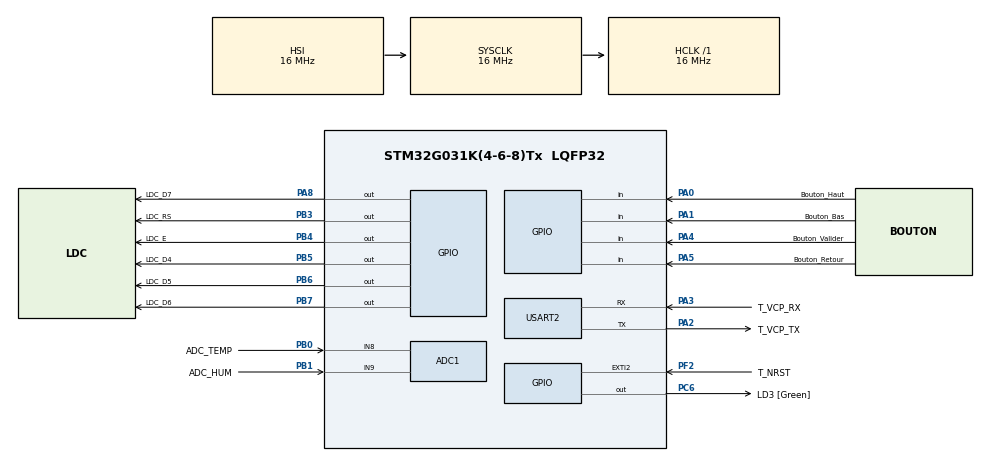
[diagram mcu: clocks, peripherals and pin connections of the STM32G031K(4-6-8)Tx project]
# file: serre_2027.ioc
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ADC1.Channel-0\#ChannelRegularConversion=ADC_CHANNEL_8
ADC1.NbrOfConversionFlag=1
ADC1.Rank-0\#ChannelRegularConversion=1
ADC1.SamplingTime-0\#ChannelRegularConversion=ADC_SAMPLINGTIME_COMMON_1
ADC1.SelectedChannel=ADC_CHANNEL_8|ADC_CHANNEL_9
ADC1.master=1
Mcu.Family=STM32G0
Mcu.Name=STM32G031K(4-6-8)Tx
Mcu.Package=LQFP32
PA0.GPIO_Label=Bouton_Haut
PA0.GPIO_PuPd=GPIO_PULLUP
PA0.Signal=GPIO_Input
PA1.GPIO_Label=Bouton_Bas
PA1.GPIO_PuPd=GPIO_PULLUP
PA1.Signal=GPIO_Input
PA13.GPIO_Label=T_JTMS
PA13.Mode=Serial_Wire
PA13.Signal=SYS_SWDIO
PA14-BOOT0.GPIO_Label=T_JTCK
PA14-BOOT0.Mode=Serial_Wire
PA14-BOOT0.Signal=SYS_SWCLK
PA2.GPIO_Label=T_VCP_TX
PA2.GPIO_PuPd=GPIO_PULLUP
PA2.Mode=Asynchronous
PA2.Signal=USART2_TX
PA3.GPIO_Label=T_VCP_RX
PA3.GPIO_PuPd=GPIO_PULLUP
PA3.Mode=Asynchronous
PA3.Signal=USART2_RX
PA4.GPIO_Label=Bouton_Valider
PA4.GPIO_PuPd=GPIO_PULLUP
PA4.Signal=GPIO_Input
PA5.GPIO_Label=Bouton_Retour
PA5.GPIO_PuPd=GPIO_PULLUP
PA5.Signal=GPIO_Input
PA8.GPIO_Label=LDC_D7
PA8.Signal=GPIO_Output
PB0.GPIO_Label=ADC_TEMP
PB0.Mode=IN8
PB0.Signal=ADC1_IN8
PB1.GPIO_Label=ADC_HUM
PB1.Mode=IN9
PB1.Signal=ADC1_IN9
PB3.GPIO_Label=LDC_RS
PB3.Signal=GPIO_Output
PB4.GPIO_Label=LDC_E
PB4.Signal=GPIO_Output
PB5.GPIO_Label=LDC_D4
PB5.Signal=GPIO_Output
PB6.GPIO_Label=LDC_D5
PB6.Signal=GPIO_Output
PB7.GPIO_Label=LDC_D6
PB7.Signal=GPIO_Output
PB8.GPIO_Label=PWM_Pompe
PB8.Signal=S_TIM16_CH1
PB9.GPIO_Label=PWM_Ventilo
PB9.Signal=S_TIM17_CH1
PC14-OSC32_IN\ (PC14).Mode=LSE-External-Oscillator
PC14-OSC32_IN\ (PC14).Signal=RCC_OSC32_IN
PC15-OSC32_OUT\ (PC15).Mode=LSE-External-Oscillator
PC15-OSC32_OUT\ (PC15).Signal=RCC_OSC32_OUT
PC6.GPIO_Label=LD3 [Green]
PC6.Signal=GPIO_Output
PF2\ -\ NRST.GPIO_Label=T_NRST
PF2\ -\ NRST.Signal=GPXTI2
ProjectManager.HeapSize=0x200
ProjectManager.StackSize=0x400
ProjectManager.TargetToolchain=STM32CubeIDE
RCC.AHBFreq_Value=16000000
RCC.CortexFreq_Value=16000000
RCC.EXTERNAL_CLOCK_VALUE=12288000
RCC.HCLKFreq_Value=16000000
RCC.HSE_VALUE=8000000
RCC.HSI_VALUE=16000000
RCC.SYSCLKFreq_VALUE=16000000
RCC.VCOOutputFreq_Value=128000000
SH.S_TIM16_CH1.0=TIM16_CH1
SH.S_TIM17_CH1.0=TIM17_CH1
USART2.VirtualMode-Asynchronous=VM_ASYNC
USART2.WordLength=WORDLENGTH_7B
board=NUCLEO-G031K8

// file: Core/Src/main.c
/* USER CODE BEGIN Header */
/**
  ******************************************************************************
  * @file           : main.c
  * @brief          : Main program body
  ******************************************************************************
  * @attention
  *
  * Copyright (c) 2026 STMicroelectronics.
  * All rights reserved.
  *
  * This software is licensed under terms that can be found in the LICENSE file
  * in the root directory of this software component.
  * If no LICENSE file comes with this software, it is provided AS-IS.
  *
  ******************************************************************************
  */
/* USER CODE END Header */
#include "main.h"

ADC_HandleTypeDef hadc1;

UART_HandleTypeDef huart2;

void SystemClock_Config(void);
static void MX_GPIO_Init(void);
static void MX_USART2_UART_Init(void);
static void MX_ADC1_Init(void);

int main(void)
{

  /* MCU Configuration--------------------------------------------------------*/

  /* Reset of all peripherals, Initializes the Flash interface and the Systick. */
  HAL_Init();

  /* Configure the system clock */
  SystemClock_Config();

  /* Initialize all configured peripherals */
  MX_GPIO_Init();
  MX_USART2_UART_Init();
  MX_ADC1_Init();

  /* Infinite loop */
  while (1)
  {

    /* USER CODE BEGIN 3 */
    HAL_GPIO_TogglePin(LD3_GPIO_Port, LD3_Pin);
    HAL_Delay(4000);
    // commentaire
    // test loris
  }
  /* USER CODE END 3 */
}

void SystemClock_Config(void)
{
  RCC_OscInitTypeDef RCC_OscInitStruct = {0};
  RCC_ClkInitTypeDef RCC_ClkInitStruct = {0};

  /** Configure the main internal regulator output voltage
  */
  HAL_PWREx_ControlVoltageScaling(PWR_REGULATOR_VOLTAGE_SCALE1);

  /** Initializes the RCC Oscillators according to the specified parameters
  * in the RCC_OscInitTypeDef structure.
  */
  RCC_OscInitStruct.OscillatorType = RCC_OSCILLATORTYPE_HSI;
  RCC_OscInitStruct.HSIState = RCC_HSI_ON;
  RCC_OscInitStruct.HSIDiv = RCC_HSI_DIV1;
  RCC_OscInitStruct.HSICalibrationValue = RCC_HSICALIBRATION_DEFAULT;
  RCC_OscInitStruct.PLL.PLLState = RCC_PLL_NONE;
  if (HAL_RCC_OscConfig(&RCC_OscInitStruct) != HAL_OK)
  {
    Error_Handler();
  }

  /** Initializes the CPU, AHB and APB buses clocks
  */
  RCC_ClkInitStruct.ClockType = RCC_CLOCKTYPE_HCLK|RCC_CLOCKTYPE_SYSCLK
                              |RCC_CLOCKTYPE_PCLK1;
  RCC_ClkInitStruct.SYSCLKSource = RCC_SYSCLKSOURCE_HSI;
  RCC_ClkInitStruct.AHBCLKDivider = RCC_SYSCLK_DIV1;
  RCC_ClkInitStruct.APB1CLKDivider = RCC_HCLK_DIV1;

  if (HAL_RCC_ClockConfig(&RCC_ClkInitStruct, FLASH_LATENCY_0) != HAL_OK)
  {
    Error_Handler();
  }
}

static void MX_ADC1_Init(void)
{

  ADC_ChannelConfTypeDef sConfig = {0};

  /** Configure the global features of the ADC (Clock, Resolution, Data Alignment and number of conversion)
  */
  hadc1.Instance = ADC1;
  hadc1.Init.ClockPrescaler = ADC_CLOCK_SYNC_PCLK_DIV2;
  hadc1.Init.Resolution = ADC_RESOLUTION_12B;
  hadc1.Init.DataAlign = ADC_DATAALIGN_RIGHT;
  hadc1.Init.ScanConvMode = ADC_SCAN_DISABLE;
  hadc1.Init.EOCSelection = ADC_EOC_SINGLE_CONV;
  hadc1.Init.LowPowerAutoWait = DISABLE;
  hadc1.Init.LowPowerAutoPowerOff = DISABLE;
  hadc1.Init.ContinuousConvMode = DISABLE;
  hadc1.Init.NbrOfConversion = 1;
  hadc1.Init.DiscontinuousConvMode = DISABLE;
  hadc1.Init.ExternalTrigConv = ADC_SOFTWARE_START;
  hadc1.Init.ExternalTrigConvEdge = ADC_EXTERNALTRIGCONVEDGE_NONE;
  hadc1.Init.DMAContinuousRequests = DISABLE;
  hadc1.Init.Overrun = ADC_OVR_DATA_PRESERVED;
  hadc1.Init.SamplingTimeCommon1 = ADC_SAMPLETIME_1CYCLE_5;
  hadc1.Init.SamplingTimeCommon2 = ADC_SAMPLETIME_1CYCLE_5;
  hadc1.Init.OversamplingMode = DISABLE;
  hadc1.Init.TriggerFrequencyMode = ADC_TRIGGER_FREQ_HIGH;
  if (HAL_ADC_Init(&hadc1) != HAL_OK)
  {
    Error_Handler();
  }

  /** Configure Regular Channel
  */
  sConfig.Channel = ADC_CHANNEL_8;
  sConfig.Rank = ADC_REGULAR_RANK_1;
  sConfig.SamplingTime = ADC_SAMPLINGTIME_COMMON_1;
  if (HAL_ADC_ConfigChannel(&hadc1, &sConfig) != HAL_OK)
  {
    Error_Handler();
  }

}

static void MX_USART2_UART_Init(void)
{

  huart2.Instance = USART2;
  huart2.Init.BaudRate = 115200;
  huart2.Init.WordLength = UART_WORDLENGTH_7B;
  huart2.Init.StopBits = UART_STOPBITS_1;
  huart2.Init.Parity = UART_PARITY_NONE;
  huart2.Init.Mode = UART_MODE_TX_RX;
  huart2.Init.HwFlowCtl = UART_HWCONTROL_NONE;
  huart2.Init.OverSampling = UART_OVERSAMPLING_16;
  huart2.Init.OneBitSampling = UART_ONE_BIT_SAMPLE_DISABLE;
  huart2.Init.ClockPrescaler = UART_PRESCALER_DIV1;
  huart2.AdvancedInit.AdvFeatureInit = UART_ADVFEATURE_NO_INIT;
  if (HAL_UART_Init(&huart2) != HAL_OK)
  {
    Error_Handler();
  }

}

static void MX_GPIO_Init(void)
{
  GPIO_InitTypeDef GPIO_InitStruct = {0};

  /* GPIO Ports Clock Enable */
  __HAL_RCC_GPIOB_CLK_ENABLE();
  __HAL_RCC_GPIOC_CLK_ENABLE();
  __HAL_RCC_GPIOF_CLK_ENABLE();
  __HAL_RCC_GPIOA_CLK_ENABLE();

  /*Configure GPIO pin Output Level */
  HAL_GPIO_WritePin(LDC_D7_GPIO_Port, LDC_D7_Pin, GPIO_PIN_RESET);

  /*Configure GPIO pin Output Level */
  HAL_GPIO_WritePin(LD3_GPIO_Port, LD3_Pin, GPIO_PIN_RESET);

  /*Configure GPIO pin Output Level */
  HAL_GPIO_WritePin(GPIOB, LDC_RS_Pin|LDC_E_Pin|LDC_D4_Pin|LDC_D5_Pin
                          |LDC_D6_Pin, GPIO_PIN_RESET);

  /*Configure GPIO pin : PWM_Ventilo_Pin */
  GPIO_InitStruct.Pin = PWM_Ventilo_Pin;
  GPIO_InitStruct.Mode = GPIO_MODE_AF_PP;
  GPIO_InitStruct.Pull = GPIO_NOPULL;
  GPIO_InitStruct.Speed = GPIO_SPEED_FREQ_LOW;
  GPIO_InitStruct.Alternate = GPIO_AF2_TIM17;
  HAL_GPIO_Init(PWM_Ventilo_GPIO_Port, &GPIO_InitStruct);

  /*Configure GPIO pin : T_NRST_Pin */
  GPIO_InitStruct.Pin = T_NRST_Pin;
  GPIO_InitStruct.Mode = GPIO_MODE_IT_RISING;
  GPIO_InitStruct.Pull = GPIO_NOPULL;
  HAL_GPIO_Init(T_NRST_GPIO_Port, &GPIO_InitStruct);

  /*Configure GPIO pins : Bouton_Haut_Pin Bouton_Bas_Pin Bouton_Valider_Pin Bouton_Retour_Pin */
  GPIO_InitStruct.Pin = Bouton_Haut_Pin|Bouton_Bas_Pin|Bouton_Valider_Pin|Bouton_Retour_Pin;
  GPIO_InitStruct.Mode = GPIO_MODE_INPUT;
  GPIO_InitStruct.Pull = GPIO_PULLUP;
  HAL_GPIO_Init(GPIOA, &GPIO_InitStruct);

  /*Configure GPIO pin : LDC_D7_Pin */
  GPIO_InitStruct.Pin = LDC_D7_Pin;
  GPIO_InitStruct.Mode = GPIO_MODE_OUTPUT_PP;
  GPIO_InitStruct.Pull = GPIO_NOPULL;
  GPIO_InitStruct.Speed = GPIO_SPEED_FREQ_LOW;
  HAL_GPIO_Init(LDC_D7_GPIO_Port, &GPIO_InitStruct);

  /*Configure GPIO pin : LD3_Pin */
  GPIO_InitStruct.Pin = LD3_Pin;
  GPIO_InitStruct.Mode = GPIO_MODE_OUTPUT_PP;
  GPIO_InitStruct.Pull = GPIO_NOPULL;
  GPIO_InitStruct.Speed = GPIO_SPEED_FREQ_LOW;
  HAL_GPIO_Init(LD3_GPIO_Port, &GPIO_InitStruct);

  /*Configure GPIO pins : LDC_RS_Pin LDC_E_Pin LDC_D4_Pin LDC_D5_Pin
                           LDC_D6_Pin */
  GPIO_InitStruct.Pin = LDC_RS_Pin|LDC_E_Pin|LDC_D4_Pin|LDC_D5_Pin
                          |LDC_D6_Pin;
  GPIO_InitStruct.Mode = GPIO_MODE_OUTPUT_PP;
  GPIO_InitStruct.Pull = GPIO_NOPULL;
  GPIO_InitStruct.Speed = GPIO_SPEED_FREQ_LOW;
  HAL_GPIO_Init(GPIOB, &GPIO_InitStruct);

  /*Configure GPIO pin : PWM_Pompe_Pin */
  GPIO_InitStruct.Pin = PWM_Pompe_Pin;
  GPIO_InitStruct.Mode = GPIO_MODE_AF_PP;
  GPIO_InitStruct.Pull = GPIO_NOPULL;
  GPIO_InitStruct.Speed = GPIO_SPEED_FREQ_LOW;
  GPIO_InitStruct.Alternate = GPIO_AF2_TIM16;
  HAL_GPIO_Init(PWM_Pompe_GPIO_Port, &GPIO_InitStruct);

}

void Error_Handler(void)
{
  __disable_irq();
  while (1)
  {
  }
}
